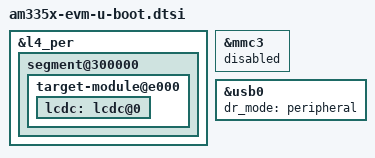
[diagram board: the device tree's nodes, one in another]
// SPDX-License-Identifier: GPL-2.0+
/*
 * Copyright (C) 2017 Texas Instruments Incorporated - http://www.ti.com/
 */

#include "am33xx-u-boot.dtsi"

&l4_per {

	segment@300000 {

		target-module@e000 {
			u-boot,dm-all;

			lcdc: lcdc@0 {
				u-boot,dm-all;
			};
		};
	};
};

&mmc3 {
	status = "disabled";
};

&usb0 {
	dr_mode = "peripheral";
};
